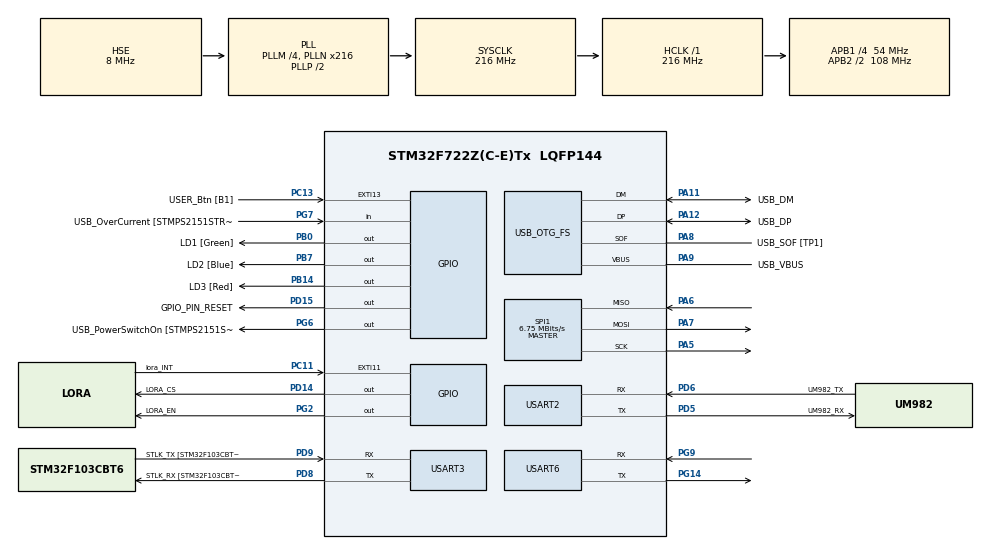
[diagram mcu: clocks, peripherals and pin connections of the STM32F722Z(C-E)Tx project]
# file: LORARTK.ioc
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CORTEX_M7.default_mode_Activation=1
Mcu.Family=STM32F7
Mcu.Name=STM32F722Z(C-E)Tx
Mcu.Package=LQFP144
DMA.Request0=USART2_RX
DMA.RequestsNb=1
DMA.USART2_RX.0.Direction=DMA_PERIPH_TO_MEMORY
DMA.USART2_RX.0.FIFOMode=DMA_FIFOMODE_DISABLE
DMA.USART2_RX.0.Instance=DMA1_Stream5
DMA.USART2_RX.0.MemDataAlignment=DMA_MDATAALIGN_BYTE
DMA.USART2_RX.0.MemInc=DMA_MINC_ENABLE
DMA.USART2_RX.0.Mode=DMA_NORMAL
DMA.USART2_RX.0.PeriphDataAlignment=DMA_PDATAALIGN_BYTE
DMA.USART2_RX.0.PeriphInc=DMA_PINC_DISABLE
DMA.USART2_RX.0.Priority=DMA_PRIORITY_VERY_HIGH
NVIC.DMA1_Stream5_IRQn=true\:5\:0\:false\:false\:true\:false\:true\:true
NVIC.EXTI15_10_IRQn=true\:0\:0\:false\:false\:true\:true\:true\:true
NVIC.PriorityGroup=NVIC_PRIORITYGROUP_4
NVIC.USART2_IRQn=true\:5\:0\:false\:false\:true\:true\:true\:true
NVIC.USART3_IRQn=true\:5\:0\:false\:false\:true\:true\:true\:true
PA10.GPIO_Label=USB_ID
PA10.Signal=USB_OTG_FS_ID
PA11.GPIO_Label=USB_DM
PA11.Mode=Device_Only
PA11.Signal=USB_OTG_FS_DM
PA12.GPIO_Label=USB_DP
PA12.Mode=Device_Only
PA12.Signal=USB_OTG_FS_DP
PA13.GPIO_Label=TMS
PA13.Mode=Serial_Wire
PA13.Signal=SYS_JTMS-SWDIO
PA14.GPIO_Label=TCK
PA14.Mode=Serial_Wire
PA14.Signal=SYS_JTCK-SWCLK
PA5.Mode=Full_Duplex_Master
PA5.Signal=SPI1_SCK
PA6.Mode=Full_Duplex_Master
PA6.Signal=SPI1_MISO
PA7.Mode=Full_Duplex_Master
PA7.Signal=SPI1_MOSI
PA8.GPIO_Label=USB_SOF [TP1]
PA8.Mode=Activate_SOF_FS
PA8.Signal=USB_OTG_FS_SOF
PA9.GPIO_Label=USB_VBUS
PA9.Mode=Activate_VBUS
PA9.Signal=USB_OTG_FS_VBUS
PB0.GPIO_Label=LD1 [Green]
PB0.Signal=GPIO_Output
PB14.GPIO_Label=LD3 [Red]
PB14.Signal=GPIO_Output
PB3.GPIO_Label=SWO
PB3.Signal=SYS_JTDO-SWO
PB7.GPIO_Label=LD2 [Blue]
PB7.Signal=GPIO_Output
PC11.GPIO_Label=lora_INT
PC11.Signal=GPXTI11
PC13.GPIO_Label=USER_Btn [B1]
PC13.Signal=GPXTI13
PC14-OSC32_IN.Mode=LSE-External-Oscillator
PC14-OSC32_IN.Signal=RCC_OSC32_IN
PC15-OSC32_OUT.Mode=LSE-External-Oscillator
PC15-OSC32_OUT.Signal=RCC_OSC32_OUT
PD14.GPIO_Label=LORA_CS
PD14.PinState=GPIO_PIN_SET
PD14.Signal=GPIO_Output
PD15.GPIO_Label=GPIO_PIN_RESET
PD15.PinState=GPIO_PIN_SET
PD15.Signal=GPIO_Output
PD5.GPIO_Label=UM982_RX
PD5.Mode=Asynchronous
PD5.Signal=USART2_TX
PD6.GPIO_Label=UM982_TX
PD6.Mode=Asynchronous
PD6.Signal=USART2_RX
PD8.GPIO_Label=STLK_RX [STM32F103CBT6_PA3]
PD8.Mode=Asynchronous
PD8.Signal=USART3_TX
PD9.GPIO_Label=STLK_TX [STM32F103CBT6_PA2]
PD9.Mode=Asynchronous
PD9.Signal=USART3_RX
PG14.Mode=Asynchronous
PG14.Signal=USART6_TX
PG2.GPIO_Label=LORA_EN
PG2.PinState=GPIO_PIN_SET
PG2.Signal=GPIO_Output
PG6.GPIO_Label=USB_PowerSwitchOn [STMPS2151STR_EN]
PG6.Signal=GPIO_Output
PG7.GPIO_Label=USB_OverCurrent [STMPS2151STR_FAULT]
PG7.Signal=GPIO_Input
PG9.Mode=Asynchronous
PG9.Signal=USART6_RX
PH0-OSC_IN.GPIO_Label=MCO
PH0-OSC_IN.Mode=HSE-External-Clock-Source
PH0-OSC_IN.Signal=RCC_OSC_IN
PH1-OSC_OUT.Mode=HSE-External-Clock-Source
PH1-OSC_OUT.Signal=RCC_OSC_OUT
ProjectManager.HeapSize=0x200
ProjectManager.StackSize=0x400
ProjectManager.TargetToolchain=STM32CubeIDE
RCC.48MHZClocksFreq_Value=24000000
RCC.AHBFreq_Value=216000000
RCC.APB1CLKDivider=RCC_HCLK_DIV4
RCC.APB1Freq_Value=54000000
RCC.APB1TimFreq_Value=108000000
RCC.APB2CLKDivider=RCC_HCLK_DIV2
RCC.APB2Freq_Value=108000000
RCC.APB2TimFreq_Value=216000000
RCC.CortexFreq_Value=216000000
RCC.HCLKFreq_Value=216000000
RCC.HSE_VALUE=8000000
RCC.HSI_VALUE=16000000
RCC.PLLM=4
RCC.PLLMUL=RCC_PLL_MUL9
RCC.PLLN=216
RCC.PLLQ=9
RCC.PRESCALERUSB=RCC_USBCLKSOURCE_PLL_DIV1_5
RCC.SYSCLKFreq_VALUE=216000000
RCC.SYSCLKSource=RCC_SYSCLKSOURCE_PLLCLK
RCC.SYSCLKSourceVirtual=RCC_SYSCLKSOURCE_PLLCLK
RCC.USBFreq_Value=48000000
RCC.VCOOutputFreq_Value=432000000
SPI1.BaudRatePrescaler=SPI_BAUDRATEPRESCALER_16
SPI1.CalculateBaudRate=6.75 MBits/s
SPI1.DataSize=SPI_DATASIZE_8BIT
SPI1.Direction=SPI_DIRECTION_2LINES
SPI1.Mode=SPI_MODE_MASTER
SPI1.VirtualType=VM_MASTER
USART2.VirtualMode-Asynchronous=VM_ASYNC
USART3.VirtualMode-Asynchronous=VM_ASYNC
USART6.VirtualMode-Asynchronous=VM_ASYNC
USB_OTG_FS.VirtualMode=Device_Only
board=NUCLEO-F722ZE

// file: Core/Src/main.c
/* USER CODE BEGIN Header */
/**
  ******************************************************************************
  * @file           : main.c
  * @brief          : Main program body
  ******************************************************************************
  * @attention
  *
  * Copyright (c) 2026 STMicroelectronics.
  * All rights reserved.
  *
  * This software is licensed under terms that can be found in the LICENSE file
  * in the root directory of this software component.
  * If no LICENSE file comes with this software, it is provided AS-IS.
  *
  ******************************************************************************
  */
/* USER CODE END Header */
#include "main.h"

/* USER CODE BEGIN Includes */
#include "lora.h"
#include "lorartk.h"
#include "rtk_bridge.h"
#include "stdio.h"        				//spintf 쓰기위해서 추가 --> printf는 모니터로 바로 출력인데, stm은 그게 없으니 내가 따로 만든 문자열 배열을 만들고 내가 모니터에 띄우고 싶은 그 문자열을 이 배열에다가 쓰는것 --> 즉 문자열 + 서식문자를 하나의 문자열로 만들어주느 느낌?
                                        //--> 이걸 따로 처리ㅣ해서 이제 uart로 이 문자열을 쏴주면 이게 출력되는거 처럼 보임
#include "string.h"						//stlren 쓰기위해서 추가 -->  strlen(data)는 현재 data에 들어있는 실제 글자 수를 세어준다. 덕분에 UART로 100개를 전부 다 보내지 않고, 딱 필요한 글자 수만큼만 깔끔하게 보낼 수 있게 해줍니다.
										// C언어 스타일의 문자열. 즉 char* str = "BlockDMask"이 문자열의 끝에는 문자열의 끝을 알려주는 '\0(=NULL)' 문자가 포함 strlen 함수의 원리는 char*가 가리키는 주소에서 부터 시작해서 '\0'이 문자가 나올때까지의 문자들의 개수를 세서 최종 길이를 반환

/* USER CODE END Includes */

SPI_HandleTypeDef hspi1;

DMA_HandleTypeDef hdma_usart2_rx;

UART_HandleTypeDef huart2;
UART_HandleTypeDef huart3;
UART_HandleTypeDef huart6;

PCD_HandleTypeDef hpcd_USB_OTG_FS;

/* USER CODE BEGIN PV */
volatile uint8_t lora_rx_flag = 0;  // rx 인터럽트 들오면 켜지는 플래그
/* USER CODE END PV */

void SystemClock_Config(void);
static void MPU_Config(void);
static void MX_GPIO_Init(void);
static void MX_USART3_UART_Init(void);
static void MX_USB_OTG_FS_PCD_Init(void);
static void MX_SPI1_Init(void);
static void MX_USART6_UART_Init(void);
static void MX_USART2_UART_Init(void);
static void MX_DMA_Init(void);

/* USER CODE BEGIN 0 */
char data1[200]="";             //시리얼프린트로 묹자 뽑기위해 저장하는 배열
/* USER CODE END 0 */

int main(void)
{

  /* MPU Configuration--------------------------------------------------------*/
  MPU_Config();

  /* MCU Configuration--------------------------------------------------------*/

  /* Reset of all peripherals, Initializes the Flash interface and the Systick. */
  HAL_Init();

  /* Configure the system clock */
  SystemClock_Config();

  /* Initialize all configured peripherals */
  MX_GPIO_Init();
  MX_DMA_Init();
  MX_USART3_UART_Init();
  MX_USB_OTG_FS_PCD_Init();
  MX_SPI1_Init();
  MX_USART6_UART_Init();
  MX_USART2_UART_Init();
  /* USER CODE BEGIN 2 */
  LORARTK_Init();
  /* USER CODE END 2 */

  /* Infinite loop */
  while (1)
  {

    /* USER CODE BEGIN 3 */
	//uart_send_noise_rssi();///////////////////////////////////////////////rssi값 매트랩에서 볼라면 이거 키기 ??  아래의 rssi_graph만 해도되는거 아닌가?

	  /*                                                    rx 시 이거 키기(이거랑 130번째줄 rx_set)
	   *
	  if(lora_rx_flag)
	  {
	      lora_rx_flag = 0;
	      rssi_graph();
	      //rx_read();   // 수신 데이터 읽고 UART 출력
	      rx_set();    // 다음 수신 대기 다시 시작
	  }*/

	  LORARTK_Process();

  }
  /* USER CODE END 3 */
}

void SystemClock_Config(void)
{
  RCC_OscInitTypeDef RCC_OscInitStruct = {0};
  RCC_ClkInitTypeDef RCC_ClkInitStruct = {0};

  /** Configure LSE Drive Capability
  */
  HAL_PWR_EnableBkUpAccess();

  /** Configure the main internal regulator output voltage
  */
  __HAL_RCC_PWR_CLK_ENABLE();
  __HAL_PWR_VOLTAGESCALING_CONFIG(PWR_REGULATOR_VOLTAGE_SCALE1);

  /** Initializes the RCC Oscillators according to the specified parameters
  * in the RCC_OscInitTypeDef structure.
  */
  RCC_OscInitStruct.OscillatorType = RCC_OSCILLATORTYPE_HSE;
  RCC_OscInitStruct.HSEState = RCC_HSE_BYPASS;
  RCC_OscInitStruct.PLL.PLLState = RCC_PLL_ON;
  RCC_OscInitStruct.PLL.PLLSource = RCC_PLLSOURCE_HSE;
  RCC_OscInitStruct.PLL.PLLM = 4;
  RCC_OscInitStruct.PLL.PLLN = 216;
  RCC_OscInitStruct.PLL.PLLP = RCC_PLLP_DIV2;
  RCC_OscInitStruct.PLL.PLLQ = 9;
  if (HAL_RCC_OscConfig(&RCC_OscInitStruct) != HAL_OK)
  {
    Error_Handler();
  }

  /** Activate the Over-Drive mode
  */
  if (HAL_PWREx_EnableOverDrive() != HAL_OK)
  {
    Error_Handler();
  }

  /** Initializes the CPU, AHB and APB buses clocks
  */
  RCC_ClkInitStruct.ClockType = RCC_CLOCKTYPE_HCLK|RCC_CLOCKTYPE_SYSCLK
                              |RCC_CLOCKTYPE_PCLK1|RCC_CLOCKTYPE_PCLK2;
  RCC_ClkInitStruct.SYSCLKSource = RCC_SYSCLKSOURCE_PLLCLK;
  RCC_ClkInitStruct.AHBCLKDivider = RCC_SYSCLK_DIV1;
  RCC_ClkInitStruct.APB1CLKDivider = RCC_HCLK_DIV4;
  RCC_ClkInitStruct.APB2CLKDivider = RCC_HCLK_DIV2;

  if (HAL_RCC_ClockConfig(&RCC_ClkInitStruct, FLASH_LATENCY_7) != HAL_OK)
  {
    Error_Handler();
  }
}

static void MX_SPI1_Init(void)
{

  /* SPI1 parameter configuration*/
  hspi1.Instance = SPI1;
  hspi1.Init.Mode = SPI_MODE_MASTER;
  hspi1.Init.Direction = SPI_DIRECTION_2LINES;
  hspi1.Init.DataSize = SPI_DATASIZE_8BIT;
  hspi1.Init.CLKPolarity = SPI_POLARITY_LOW;
  hspi1.Init.CLKPhase = SPI_PHASE_1EDGE;
  hspi1.Init.NSS = SPI_NSS_SOFT;
  hspi1.Init.BaudRatePrescaler = SPI_BAUDRATEPRESCALER_16;
  hspi1.Init.FirstBit = SPI_FIRSTBIT_MSB;
  hspi1.Init.TIMode = SPI_TIMODE_DISABLE;
  hspi1.Init.CRCCalculation = SPI_CRCCALCULATION_DISABLE;
  hspi1.Init.CRCPolynomial = 7;
  hspi1.Init.CRCLength = SPI_CRC_LENGTH_DATASIZE;
  hspi1.Init.NSSPMode = SPI_NSS_PULSE_ENABLE;
  if (HAL_SPI_Init(&hspi1) != HAL_OK)
  {
    Error_Handler();
  }

}

static void MX_USART2_UART_Init(void)
{

  huart2.Instance = USART2;
  huart2.Init.BaudRate = 115200;
  huart2.Init.WordLength = UART_WORDLENGTH_8B;
  huart2.Init.StopBits = UART_STOPBITS_1;
  huart2.Init.Parity = UART_PARITY_NONE;
  huart2.Init.Mode = UART_MODE_TX_RX;
  huart2.Init.HwFlowCtl = UART_HWCONTROL_NONE;
  huart2.Init.OverSampling = UART_OVERSAMPLING_16;
  huart2.Init.OneBitSampling = UART_ONE_BIT_SAMPLE_DISABLE;
  huart2.AdvancedInit.AdvFeatureInit = UART_ADVFEATURE_NO_INIT;
  if (HAL_UART_Init(&huart2) != HAL_OK)
  {
    Error_Handler();
  }

}

static void MX_USART3_UART_Init(void)
{

  huart3.Instance = USART3;
  huart3.Init.BaudRate = 115200;
  huart3.Init.WordLength = UART_WORDLENGTH_8B;
  huart3.Init.StopBits = UART_STOPBITS_1;
  huart3.Init.Parity = UART_PARITY_NONE;
  huart3.Init.Mode = UART_MODE_TX_RX;
  huart3.Init.HwFlowCtl = UART_HWCONTROL_NONE;
  huart3.Init.OverSampling = UART_OVERSAMPLING_16;
  huart3.Init.OneBitSampling = UART_ONE_BIT_SAMPLE_DISABLE;
  huart3.AdvancedInit.AdvFeatureInit = UART_ADVFEATURE_NO_INIT;
  if (HAL_UART_Init(&huart3) != HAL_OK)
  {
    Error_Handler();
  }

}

static void MX_USART6_UART_Init(void)
{

  huart6.Instance = USART6;
  huart6.Init.BaudRate = 115200;
  huart6.Init.WordLength = UART_WORDLENGTH_8B;
  huart6.Init.StopBits = UART_STOPBITS_1;
  huart6.Init.Parity = UART_PARITY_NONE;
  huart6.Init.Mode = UART_MODE_TX_RX;
  huart6.Init.HwFlowCtl = UART_HWCONTROL_NONE;
  huart6.Init.OverSampling = UART_OVERSAMPLING_16;
  huart6.Init.OneBitSampling = UART_ONE_BIT_SAMPLE_DISABLE;
  huart6.AdvancedInit.AdvFeatureInit = UART_ADVFEATURE_NO_INIT;
  if (HAL_UART_Init(&huart6) != HAL_OK)
  {
    Error_Handler();
  }

}

static void MX_USB_OTG_FS_PCD_Init(void)
{

  hpcd_USB_OTG_FS.Instance = USB_OTG_FS;
  hpcd_USB_OTG_FS.Init.dev_endpoints = 6;
  hpcd_USB_OTG_FS.Init.speed = PCD_SPEED_FULL;
  hpcd_USB_OTG_FS.Init.dma_enable = DISABLE;
  hpcd_USB_OTG_FS.Init.phy_itface = PCD_PHY_EMBEDDED;
  hpcd_USB_OTG_FS.Init.Sof_enable = ENABLE;
  hpcd_USB_OTG_FS.Init.low_power_enable = DISABLE;
  hpcd_USB_OTG_FS.Init.lpm_enable = DISABLE;
  hpcd_USB_OTG_FS.Init.battery_charging_enable = ENABLE;
  hpcd_USB_OTG_FS.Init.vbus_sensing_enable = ENABLE;
  hpcd_USB_OTG_FS.Init.use_dedicated_ep1 = DISABLE;
  if (HAL_PCD_Init(&hpcd_USB_OTG_FS) != HAL_OK)
  {
    Error_Handler();
  }

}

static void MX_DMA_Init(void)
{
  __HAL_RCC_DMA1_CLK_ENABLE();

  HAL_NVIC_SetPriority(DMA1_Stream5_IRQn, 5, 0);
  HAL_NVIC_EnableIRQ(DMA1_Stream5_IRQn);
}

static void MX_GPIO_Init(void)
{
  GPIO_InitTypeDef GPIO_InitStruct = {0};

  /* GPIO Ports Clock Enable */
  __HAL_RCC_GPIOC_CLK_ENABLE();
  __HAL_RCC_GPIOH_CLK_ENABLE();
  __HAL_RCC_GPIOA_CLK_ENABLE();
  __HAL_RCC_GPIOB_CLK_ENABLE();
  __HAL_RCC_GPIOD_CLK_ENABLE();
  __HAL_RCC_GPIOG_CLK_ENABLE();

  /*Configure GPIO pin Output Level */
  HAL_GPIO_WritePin(GPIOB, LD1_Pin|LD3_Pin|LD2_Pin, GPIO_PIN_RESET);

  /*Configure GPIO pin Output Level */
  HAL_GPIO_WritePin(GPIOD, LORA_CS_Pin|GPIO_PIN_RESET_Pin, GPIO_PIN_SET);

  /*Configure GPIO pin Output Level */
  HAL_GPIO_WritePin(LORA_EN_GPIO_Port, LORA_EN_Pin, GPIO_PIN_SET);

  /*Configure GPIO pin Output Level */
  HAL_GPIO_WritePin(USB_PowerSwitchOn_GPIO_Port, USB_PowerSwitchOn_Pin, GPIO_PIN_RESET);

  /*Configure GPIO pins : USER_Btn_Pin lora_INT_Pin */
  GPIO_InitStruct.Pin = USER_Btn_Pin|lora_INT_Pin;
  GPIO_InitStruct.Mode = GPIO_MODE_IT_RISING;
  GPIO_InitStruct.Pull = GPIO_NOPULL;
  HAL_GPIO_Init(GPIOC, &GPIO_InitStruct);

  /*Configure GPIO pins : LD1_Pin LD3_Pin LD2_Pin */
  GPIO_InitStruct.Pin = LD1_Pin|LD3_Pin|LD2_Pin;
  GPIO_InitStruct.Mode = GPIO_MODE_OUTPUT_PP;
  GPIO_InitStruct.Pull = GPIO_NOPULL;
  GPIO_InitStruct.Speed = GPIO_SPEED_FREQ_LOW;
  HAL_GPIO_Init(GPIOB, &GPIO_InitStruct);

  /*Configure GPIO pins : LORA_CS_Pin PDPin */
  GPIO_InitStruct.Pin = LORA_CS_Pin|GPIO_PIN_RESET_Pin;
  GPIO_InitStruct.Mode = GPIO_MODE_OUTPUT_PP;
  GPIO_InitStruct.Pull = GPIO_NOPULL;
  GPIO_InitStruct.Speed = GPIO_SPEED_FREQ_LOW;
  HAL_GPIO_Init(GPIOD, &GPIO_InitStruct);

  /*Configure GPIO pins : LORA_EN_Pin USB_PowerSwitchOn_Pin */
  GPIO_InitStruct.Pin = LORA_EN_Pin|USB_PowerSwitchOn_Pin;
  GPIO_InitStruct.Mode = GPIO_MODE_OUTPUT_PP;
  GPIO_InitStruct.Pull = GPIO_NOPULL;
  GPIO_InitStruct.Speed = GPIO_SPEED_FREQ_LOW;
  HAL_GPIO_Init(GPIOG, &GPIO_InitStruct);

  /*Configure GPIO pin : USB_OverCurrent_Pin */
  GPIO_InitStruct.Pin = USB_OverCurrent_Pin;
  GPIO_InitStruct.Mode = GPIO_MODE_INPUT;
  GPIO_InitStruct.Pull = GPIO_NOPULL;
  HAL_GPIO_Init(USB_OverCurrent_GPIO_Port, &GPIO_InitStruct);

  /* EXTI interrupt init*/
  HAL_NVIC_SetPriority(EXTI15_10_IRQn, 0, 0);
  HAL_NVIC_EnableIRQ(EXTI15_10_IRQn);

}

/* USER CODE BEGIN 4 */
void HAL_GPIO_EXTI_Callback(uint16_t GPIO_Pin)
{
    if(GPIO_Pin == lora_INT_Pin)
    {
        lora_rx_flag = 1;
    }
}

/* USER CODE END 4 */

 /* MPU Configuration */

void MPU_Config(void)
{
  MPU_Region_InitTypeDef MPU_InitStruct = {0};

  /* Disables the MPU */
  HAL_MPU_Disable();

  /** Initializes and configures the Region and the memory to be protected
  */
  MPU_InitStruct.Enable = MPU_REGION_ENABLE;
  MPU_InitStruct.Number = MPU_REGION_NUMBER0;
  MPU_InitStruct.BaseAddress = 0x0;
  MPU_InitStruct.Size = MPU_REGION_SIZE_4GB;
  MPU_InitStruct.SubRegionDisable = 0x87;
  MPU_InitStruct.TypeExtField = MPU_TEX_LEVEL0;
  MPU_InitStruct.AccessPermission = MPU_REGION_NO_ACCESS;
  MPU_InitStruct.DisableExec = MPU_INSTRUCTION_ACCESS_DISABLE;
  MPU_InitStruct.IsShareable = MPU_ACCESS_SHAREABLE;
  MPU_InitStruct.IsCacheable = MPU_ACCESS_NOT_CACHEABLE;
  MPU_InitStruct.IsBufferable = MPU_ACCESS_NOT_BUFFERABLE;

  HAL_MPU_ConfigRegion(&MPU_InitStruct);
  /* Enables the MPU */
  HAL_MPU_Enable(MPU_PRIVILEGED_DEFAULT);

}

void Error_Handler(void)
{
  __disable_irq();
  while (1)
  {
  }
}
